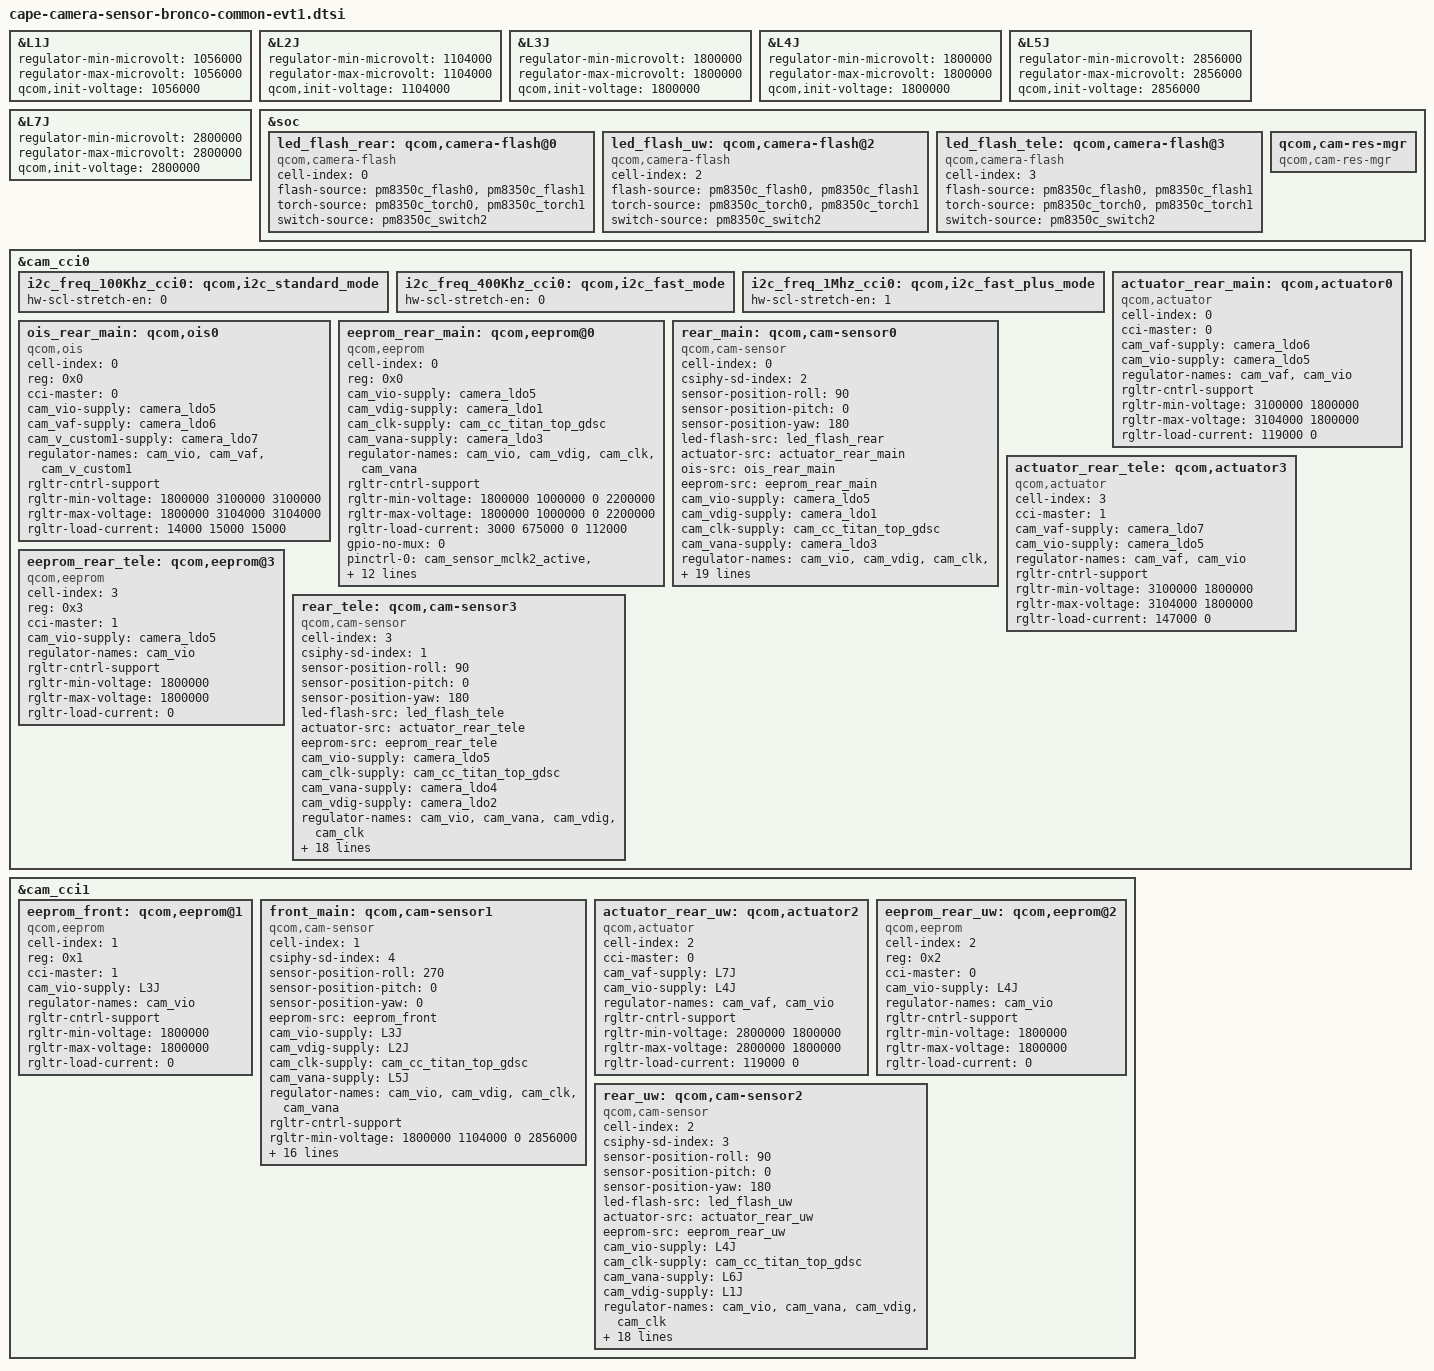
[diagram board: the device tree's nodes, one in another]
/*
   This base is original from "waipio-camera-sensor-mtp.dtsi"
*/
#include <dt-bindings/clock/qcom,camcc-waipio.h>



&L1J {
	regulator-min-microvolt = <1056000>;
	regulator-max-microvolt = <1056000>;
	qcom,init-voltage = <1056000>;
};

&L2J {
	regulator-min-microvolt = <1104000>;
	regulator-max-microvolt = <1104000>;
	qcom,init-voltage = <1104000>;
};

&L3J {
	regulator-min-microvolt = <1800000>;
	regulator-max-microvolt = <1800000>;
	qcom,init-voltage = <1800000>;
};

&L4J {
	regulator-min-microvolt = <1800000>;
	regulator-max-microvolt = <1800000>;
	qcom,init-voltage = <1800000>;
};

&L5J {
	regulator-min-microvolt = <2856000>;
	regulator-max-microvolt = <2856000>;
	qcom,init-voltage = <2856000>;
};

&L7J {
	regulator-min-microvolt = <2800000>;
	regulator-max-microvolt = <2800000>;
	qcom,init-voltage = <2800000>;
};
&soc {
	led_flash_rear: qcom,camera-flash@0 {
		cell-index = <0>;
		compatible = "qcom,camera-flash";
		flash-source = <&pm8350c_flash0 &pm8350c_flash1>;
		torch-source = <&pm8350c_torch0 &pm8350c_torch1>;
		switch-source = <&pm8350c_switch2>;
		status = "ok";
	};

	led_flash_uw: qcom,camera-flash@2 {
		cell-index = <2>;
		compatible = "qcom,camera-flash";
		flash-source = <&pm8350c_flash0 &pm8350c_flash1>;
		torch-source = <&pm8350c_torch0 &pm8350c_torch1>;
		switch-source = <&pm8350c_switch2>;
		status = "ok";
	};

	led_flash_tele: qcom,camera-flash@3 {
		cell-index = <3>;
		compatible = "qcom,camera-flash";
		flash-source = <&pm8350c_flash0 &pm8350c_flash1>;
		torch-source = <&pm8350c_torch0 &pm8350c_torch1>;
		switch-source = <&pm8350c_switch2>;
		status = "ok";
	};

	qcom,cam-res-mgr {
		compatible = "qcom,cam-res-mgr";
		status = "ok";
	};
};

&cam_cci0 {
	i2c_freq_100Khz_cci0: qcom,i2c_standard_mode {
		hw-scl-stretch-en = <0>;
	};

	i2c_freq_400Khz_cci0: qcom,i2c_fast_mode {
		hw-scl-stretch-en = <0>;
	};

	i2c_freq_1Mhz_cci0: qcom,i2c_fast_plus_mode {
		hw-scl-stretch-en = <1>;
	};

	actuator_rear_main: qcom,actuator0 {
		cell-index = <0>;
		compatible = "qcom,actuator";
		cci-master = <0>;
		cam_vaf-supply = <&camera_ldo6>;
		cam_vio-supply = <&camera_ldo5>;
		regulator-names = "cam_vaf", "cam_vio";
		rgltr-cntrl-support;
		rgltr-min-voltage = <3100000 1800000>;
		rgltr-max-voltage = <3104000 1800000>; /*step is 0.008V, can't exactly equal to 3.1V*/
		rgltr-load-current = <119000 0>;
	};

	ois_rear_main: qcom,ois0 {
		cell-index = <0>;
		reg = <0x0>;
		compatible = "qcom,ois";
		cci-master = <0>;
		cam_vio-supply = <&camera_ldo5>;
		cam_vaf-supply = <&camera_ldo6>;
		cam_v_custom1-supply = <&camera_ldo7>;
		regulator-names = "cam_vio", "cam_vaf", "cam_v_custom1";
		rgltr-cntrl-support;
		rgltr-min-voltage = <1800000 3100000 3100000>;
		rgltr-max-voltage = <1800000 3104000 3104000>;
		rgltr-load-current = <14000 15000 15000>;
		status = "ok";
	};

	eeprom_rear_main: qcom,eeprom@0 {
		cell-index = <0>;
		reg = <0x0>;
		compatible = "qcom,eeprom";
		cam_vio-supply = <&camera_ldo5>;
		cam_vdig-supply = <&camera_ldo1>;
		cam_clk-supply = <&cam_cc_titan_top_gdsc>;
		cam_vana-supply = <&camera_ldo3>;
		regulator-names = "cam_vio", "cam_vdig",
			"cam_clk", "cam_vana";
		rgltr-cntrl-support;
		rgltr-min-voltage = <1800000 1000000 0 2200000>;
		rgltr-max-voltage = <1800000 1000000 0 2200000>;
		rgltr-load-current = <3000 675000 0 112000>;
		gpio-no-mux = <0>;
		pinctrl-names = "cam_default", "cam_suspend";
		pinctrl-0 = <&cam_sensor_mclk2_active
			&cam_sensor_active_rst2>;
		pinctrl-1 = <&cam_sensor_mclk2_suspend
			&cam_sensor_suspend_rst2>;
		gpios = <&tlmm 102 0>,
			<&tlmm 117 0>;
		gpio-reset = <1>;
		gpio-req-tbl-num = <0 1>;
		gpio-req-tbl-flags = <1 0>;
		gpio-req-tbl-label = "CAMIF_MCLK2",
					"CAM_RESET2";
		cci-master = <0>;
		clocks = <&clock_camcc CAM_CC_MCLK2_CLK>;
		clock-names = "cam_clk";
		clock-cntl-level = "nominal";
		clock-rates = <19200000>;
		status = "ok";
	};

	rear_main: qcom,cam-sensor0 {
		cell-index = <0>;
		compatible = "qcom,cam-sensor";
		csiphy-sd-index = <2>;
		sensor-position-roll = <90>;
		sensor-position-pitch = <0>;
		sensor-position-yaw = <180>;
		led-flash-src = <&led_flash_rear>;
		actuator-src = <&actuator_rear_main>;
		ois-src = <&ois_rear_main>;
		eeprom-src = <&eeprom_rear_main>;
		cam_vio-supply = <&camera_ldo5>;
		cam_vdig-supply = <&camera_ldo1>;
		cam_clk-supply = <&cam_cc_titan_top_gdsc>;
		cam_vana-supply = <&camera_ldo3>;
		regulator-names = "cam_vio", "cam_vdig",
			"cam_clk", "cam_vana";
		rgltr-cntrl-support;
		rgltr-min-voltage = <1800000 1000000 0 2200000>;
		rgltr-max-voltage = <1800000 1000000 0 2200000>;
		rgltr-load-current = <3000 675000 0 112000>;
		gpio-no-mux = <0>;
		pinctrl-names = "cam_default", "cam_suspend";
		pinctrl-0 = <&cam_sensor_mclk2_active
			&cam_sensor_active_rst2>;
		pinctrl-1 = <&cam_sensor_mclk2_suspend
			&cam_sensor_suspend_rst2>;
		gpios = <&tlmm 102 0>,
			<&tlmm 117 0>;
		gpio-reset = <1>;
		gpio-req-tbl-num = <0 1>;
		gpio-req-tbl-flags = <1 0>;
		gpio-req-tbl-label = "CAMIF_MCLK2",
					"CAM_RESET2";
		cci-master = <0>;
		clocks = <&clock_camcc CAM_CC_MCLK2_CLK>;
		clock-names = "cam_clk";
		clock-cntl-level = "nominal";
		clock-rates = <19200000>;
		status = "ok";
	};

	actuator_rear_tele: qcom,actuator3 {
		cell-index = <3>;
		compatible = "qcom,actuator";
		cci-master = <1>;
		cam_vaf-supply = <&camera_ldo7>;
		cam_vio-supply = <&camera_ldo5>;
		regulator-names = "cam_vaf", "cam_vio";
		rgltr-cntrl-support;
		rgltr-min-voltage = <3100000 1800000>;
		rgltr-max-voltage = <3104000 1800000>;
		rgltr-load-current = <147000 0>;
	};

	eeprom_rear_tele: qcom,eeprom@3 {
		cell-index = <3>;
		reg = <0x3>;
		compatible = "qcom,eeprom";
		cci-master = <1>;
		cam_vio-supply = <&camera_ldo5>;
		regulator-names = "cam_vio";
		rgltr-cntrl-support;
		rgltr-min-voltage = <1800000>;
		rgltr-max-voltage = <1800000>;
		rgltr-load-current = <0>;
	};

	rear_tele: qcom,cam-sensor3 {
		cell-index = <3>;
		compatible = "qcom,cam-sensor";
		csiphy-sd-index = <1>;
		sensor-position-roll = <90>;
		sensor-position-pitch = <0>;
		sensor-position-yaw = <180>;
		led-flash-src = <&led_flash_tele>;
		actuator-src = <&actuator_rear_tele>;
		eeprom-src = <&eeprom_rear_tele>;
		cam_vio-supply = <&camera_ldo5>;
		cam_clk-supply = <&cam_cc_titan_top_gdsc>;
		cam_vana-supply = <&camera_ldo4>;
		cam_vdig-supply = <&camera_ldo2>;
		regulator-names = "cam_vio", "cam_vana",
			"cam_vdig", "cam_clk";
		rgltr-cntrl-support;
		rgltr-min-voltage = <1800000 2800000 1056000 0>;
		rgltr-max-voltage = <1800000 2800000 1056000 0>;
		rgltr-load-current = <3300 159000 79000 0>;
		gpio-no-mux = <0>;
		pinctrl-names = "cam_default", "cam_suspend";
		pinctrl-0 = <&cam_sensor_mclk1_active
			&cam_sensor_active_rst1>;
		pinctrl-1 = <&cam_sensor_mclk1_suspend
			&cam_sensor_suspend_rst1>;
		gpios = <&tlmm 101 0>,
			<&tlmm 24 0>;
		gpio-reset = <1>;
		gpio-req-tbl-num = <0 1>;
		gpio-req-tbl-flags = <1 0>;
		gpio-req-tbl-label = "CAMIF_MCLK1",
			"CAM_RESET1";
		cci-master = <1>;
		clocks = <&clock_camcc CAM_CC_MCLK1_CLK>;
		clock-names = "cam_clk";
		clock-cntl-level = "nominal";
		clock-rates = <19200000>;
		status = "ok";
	};
};

&cam_cci1 {
	eeprom_front: qcom,eeprom@1 {
		cell-index = <1>;
		reg = <0x1>;
		compatible = "qcom,eeprom";
		cci-master = <1>;
		cam_vio-supply = <&L3J>;
		regulator-names = "cam_vio";
		rgltr-cntrl-support;
		rgltr-min-voltage = <1800000>;
		rgltr-max-voltage = <1800000>;
		rgltr-load-current = <0>;
	};

	front_main: qcom,cam-sensor1 {
		cell-index = <1>;
		compatible = "qcom,cam-sensor";
		csiphy-sd-index = <4>;
		sensor-position-roll = <270>;
		sensor-position-pitch = <0>;
		sensor-position-yaw = <0>;
		eeprom-src = <&eeprom_front>;
		cam_vio-supply = <&L3J>;
		cam_vdig-supply = <&L2J>;
		cam_clk-supply = <&cam_cc_titan_top_gdsc>;
		cam_vana-supply = <&L5J>;
		regulator-names = "cam_vio", "cam_vdig",
			"cam_clk", "cam_vana";
		rgltr-cntrl-support;
		rgltr-min-voltage = <1800000 1104000 0 2856000>;
		rgltr-max-voltage = <1800000 1104000 0 2856000>;
		rgltr-load-current = <3000 125000 0 95000>;
		gpio-no-mux = <0>;
		pinctrl-names = "cam_default", "cam_suspend";
		pinctrl-0 = <&cam_sensor_mclk4_active
			&cam_sensor_active_rst6>;
		pinctrl-1 = <&cam_sensor_mclk4_suspend
			&cam_sensor_suspend_rst6>;
		gpios = <&tlmm 104 0>,
			<&tlmm 108 0>;
		gpio-reset = <1>;
		gpio-req-tbl-num = <0 1>;
		gpio-req-tbl-flags = <1 0>;
		gpio-req-tbl-label = "CAMIF_MCLK4",
					"CAM_RESET4";
		cci-master = <1>;
		clocks = <&clock_camcc CAM_CC_MCLK4_CLK>;
		clock-names = "cam_clk";
		clock-cntl-level = "nominal";
		clock-rates = <24000000>;
		status = "ok";
	};

	actuator_rear_uw: qcom,actuator2 {
		cell-index = <2>;
		compatible = "qcom,actuator";
		cci-master = <0>;
		cam_vaf-supply = <&L7J>;
		cam_vio-supply = <&L4J>;
		regulator-names = "cam_vaf", "cam_vio";
		rgltr-cntrl-support;
		rgltr-min-voltage = <2800000 1800000>;
		rgltr-max-voltage = <2800000 1800000>;
		rgltr-load-current = <119000 0>;
	};

	eeprom_rear_uw: qcom,eeprom@2 {
		cell-index = <2>;
		reg = <0x2>;
		compatible = "qcom,eeprom";
		cci-master = <0>;
		cam_vio-supply = <&L4J>;
		regulator-names = "cam_vio";
		rgltr-cntrl-support;
		rgltr-min-voltage = <1800000>;
		rgltr-max-voltage = <1800000>;
		rgltr-load-current = <0>;
	};

	rear_uw: qcom,cam-sensor2 {
		cell-index = <2>;
		compatible = "qcom,cam-sensor";
		csiphy-sd-index = <3>;
		sensor-position-roll = <90>;
		sensor-position-pitch = <0>;
		sensor-position-yaw = <180>;
		led-flash-src = <&led_flash_uw>;
		actuator-src = <&actuator_rear_uw>;
		eeprom-src = <&eeprom_rear_uw>;
		cam_vio-supply = <&L4J>;
		cam_clk-supply = <&cam_cc_titan_top_gdsc>;
		cam_vana-supply = <&L6J>;
		cam_vdig-supply = <&L1J>;
		regulator-names = "cam_vio", "cam_vana",
			"cam_vdig", "cam_clk";
		rgltr-cntrl-support;
		rgltr-min-voltage = <1800000 2800000 1056000 0>;
		rgltr-max-voltage = <1800000 2800000 1056000 0>;
		rgltr-load-current = <3000 148000 212000 0>;
		gpio-no-mux = <0>;
		pinctrl-names = "cam_default", "cam_suspend";
		pinctrl-0 = <&cam_sensor_mclk3_active
			&cam_sensor_active_rst3>;
		pinctrl-1 = <&cam_sensor_mclk3_suspend
			&cam_sensor_suspend_rst3>;
		gpios = <&tlmm 103 0>,
			<&tlmm 120 0>;
		gpio-reset = <1>;
		gpio-req-tbl-num = <0 1>;
		gpio-req-tbl-flags = <1 0>;
		gpio-req-tbl-label = "CAMIF_MCLK3",
			"CAM_RESET3";
		cci-master = <0>;
		clocks = <&clock_camcc CAM_CC_MCLK3_CLK>;
		clock-names = "cam_clk";
		clock-cntl-level = "nominal";
		clock-rates = <24000000>;
		status = "ok";
	};
};
